# MIMXRT1052 register map
Vendor: nxp.com; File version: 1.0
CPU: CM7 r0p1, little endian, MPU, FPU, VTOR, 4 interrupt priority bits
Registers are 32-bit, read-write, reset 0x0 unless marked. A register's access mark holds for its fields unless they carry their own. Offsets are from the block's base; [hi:lo] are bit positions; {n}, {i} and the like mark numbered series; 'fields as' and 'values as' point back to an identical list.

## IOMUXC_GPR
Base 0x400AC000; register names take the prefix IOMUXC_GPR_
0x00 GPR0 ro — GPR0 General Purpose Register
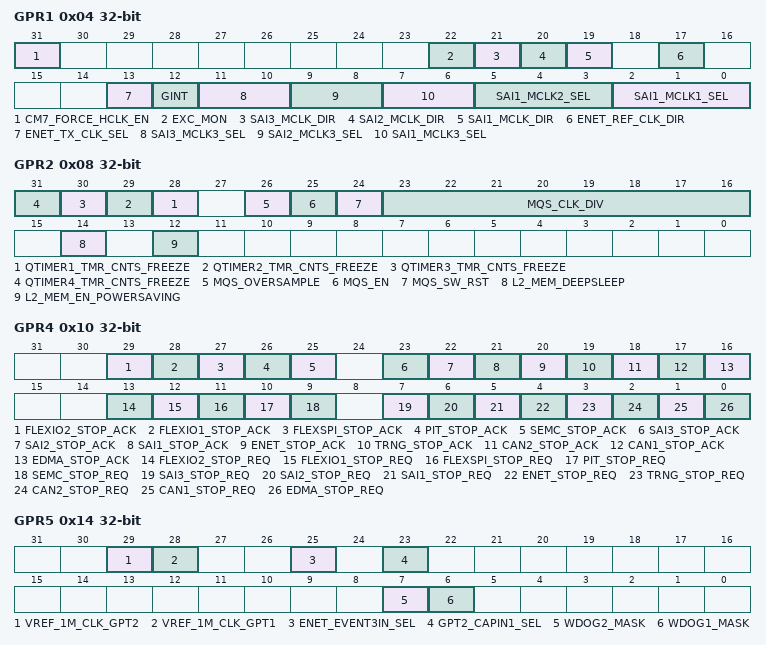
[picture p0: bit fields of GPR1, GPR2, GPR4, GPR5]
0x04 GPR1 — GPR1 General Purpose Register
  [31] CM7_FORCE_HCLK_EN — Arm CM7 platform AHB clock enable
    0=AHB clock is not running (gated) when CM7 is sleeping and TCM is not accessible; 1=AHB clock is running (enabled) when CM7 is sleeping and TCM is accessible
  [22] EXC_MON — Exclusive monitor response select of illegal command
    0=OKAY response; 1=SLVError response
  [21] SAI3_MCLK_DIR — SAI3_MCLK signal direction control. Sets the direction for the SAI3_MCLK pin function.
    0=SAI3_MCLK is input signal; 1=SAI3_MCLK is output signal
  [20] SAI2_MCLK_DIR — SAI2_MCLK signal direction control. Sets the direction for the SAI2_MCLK pin function.
    0=SAI2_MCLK is input signal; 1=SAI2_MCLK is output signal
  [19] SAI1_MCLK_DIR — SAI1_MCLK signal direction control. Sets the direction for the SAI1_MCLK pin function.
    0=SAI1_MCLK is input signal; 1=SAI1_MCLK is output signal
  [17] ENET_REF_CLK_DIR — ENET_REF_CLK direction control
    0=ENET_REF_CLK is input; 1=ENET_REF_CLK is output driven by ref_enetpll0
  [13] ENET_TX_CLK_SEL — ENET_TX_CLK select
    0=Do not use; 1=ENET_TX_CLK is the 25MHz MII clock
  [12] GINT — Global Interrupt
    0=Global interrupt request is not asserted; 1=Global interrupt request is asserted. Interrupt is issued to Arm M7 IRQ#41 and GPC
  [11:10] SAI3_MCLK3_SEL — SAI3 MCLK3 source select
    0=ccm.spdif0_clk_root; 1=iomux.spdif_tx_clk2; 2=spdif.spdif_srclk; 3=spdif.spdif_outclock
  [9:8] SAI2_MCLK3_SEL — SAI2 MCLK3 source select
    values as SAI3_MCLK3_SEL
  [7:6] SAI1_MCLK3_SEL — SAI1 MCLK3 source select
    values as SAI3_MCLK3_SEL
  [5:3] SAI1_MCLK2_SEL — SAI1 MCLK2 source select
    0=SAI1_CLK_ROOT; 1=SAI2_CLK_ROOT; 2=SAI3_CLK_ROOT; 3=iomux.sai1_ipg_clk_sai_mclk; 4=iomux.sai2_ipg_clk_sai_mclk; 5=iomux.sai3_ipg_clk_sai_mclk
  [2:0] SAI1_MCLK1_SEL — SAI1 MCLK1 source select
    values as SAI1_MCLK2_SEL
0x08 GPR2 — GPR2 General Purpose Register
  [n+27] QTIMER{n}_TMR_CNTS_FREEZE (n=1..4) — QTIMER{n} timer counter freeze
    0=Timer counter works normally; 1=Reset counter and ouput flags
  [26] MQS_OVERSAMPLE — Medium Quality Sound (MQS) Oversample
    0=32; 1=64
  [25] MQS_EN — MQS enable.
    0=Disable MQS; 1=Enable MQS
  [24] MQS_SW_RST — MQS software reset
    0=Exit software reset for MQS; 1=Enable software reset for MQS
  [23:16] MQS_CLK_DIV — Divider ratio control for mclk from hmclk. mclk frequency = 1/(n+1) * hmclk frequency.
    {v}=DIVIDE_{v+1} (mclk frequency = 1/{v+1} * hmclk frequency) (v=0..255)
  [14] L2_MEM_DEEPSLEEP — This bit controls how memory (OCRAM) enters Deep Sleep mode (shutdown periphery power, but maintain memory contents, outputs of memory are pulled low)
    0=No force sleep control supported, memory deep sleep mode only entered when whole system in stop mode (OCRAM in normal mode); 1=Force memory into deep sleep mode (OCRAM in power saving mode)
  [12] L2_MEM_EN_POWERSAVING — Enable power saving features on memory
    0=Enters power saving mode only when chip is in SUSPEND mode; 1=Controlled by L2_MEM_DEEPSLEEP bitfield
0x0C GPR3 reset 0xFFF0 — GPR3 General Purpose Register
  [4] DCP_KEY_SEL — Select 128-bit DCP key from 256-bit key from SNVS Master Key
    0=Select [127:0] from SNVS Master Key as DCP key; 1=Select [255:128] from SNVS Master Key as DCP key
0x10 GPR4 — GPR4 General Purpose Register
  [29] FLEXIO2_STOP_ACK ro — FLEXIO2 stop acknowledge
    0=FLEXIO2 stop acknowledge is not asserted; 1=FLEXIO2 stop acknowledge is asserted (FLEXIO2 is in STOP mode)
  [28] FLEXIO1_STOP_ACK ro — FLEXIO1 stop acknowledge
    0=FLEXIO1 stop acknowledge is not asserted; 1=FLEXIO1 stop acknowledge is asserted
  [27] FLEXSPI_STOP_ACK ro — FLEXSPI stop acknowledge
    0=FLEXSPI stop acknowledge is not asserted; 1=FLEXSPI stop acknowledge is asserted
  [26] PIT_STOP_ACK ro — PIT stop acknowledge
    0=PIT stop acknowledge is not asserted; 1=PIT stop acknowledge is asserted
  [25] SEMC_STOP_ACK ro — SEMC stop acknowledge
    0=SEMC stop acknowledge is not asserted; 1=SEMC stop acknowledge is asserted
  [23] SAI3_STOP_ACK ro — SAI3 stop acknowledge
    0=SAI3 stop acknowledge is not asserted; 1=SAI3 stop acknowledge is asserted
  [22] SAI2_STOP_ACK ro — SAI2 stop acknowledge
    0=SAI2 stop acknowledge is not asserted; 1=SAI2 stop acknowledge is asserted
  [21] SAI1_STOP_ACK ro — SAI1 stop acknowledge
    0=SAI1 stop acknowledge is not asserted; 1=SAI1 stop acknowledge is asserted
  [20] ENET_STOP_ACK ro — ENET stop acknowledge
    0=ENET stop acknowledge is not asserted; 1=ENET stop acknowledge is asserted
  [19] TRNG_STOP_ACK ro — TRNG stop acknowledge
    0=TRNG stop acknowledge is not asserted; 1=TRNG stop acknowledge is asserted
  [18] CAN2_STOP_ACK ro — CAN2 stop acknowledge
    0=CAN2 stop acknowledge is not asserted; 1=CAN2 stop acknowledge is asserted
  [17] CAN1_STOP_ACK ro — CAN1 stop acknowledge
    0=CAN1 stop acknowledge is not asserted; 1=CAN1 stop acknowledge is asserted
  [16] EDMA_STOP_ACK ro — EDMA stop acknowledge
    0=EDMA stop acknowledge is not asserted; 1=EDMA stop acknowledge is asserted (EDMA is in STOP mode)
  [13] FLEXIO2_STOP_REQ — FlexIO2 stop request
    0=stop request off; 1=stop request on
  [12] FLEXIO1_STOP_REQ — FlexIO1 stop request
    0=stop request off; 1=stop request on
  [11] FLEXSPI_STOP_REQ — FlexSPI stop request
    0=stop request off; 1=stop request on
  [10] PIT_STOP_REQ — PIT stop request
    0=stop request off; 1=stop request on
  [9] SEMC_STOP_REQ — SEMC stop request
    0=stop request off; 1=stop request on
  [7] SAI3_STOP_REQ — SAI3 stop request
    0=stop request off; 1=stop request on
  [6] SAI2_STOP_REQ — SAI2 stop request
    0=stop request off; 1=stop request on
  [5] SAI1_STOP_REQ — SAI1 stop request
    0=stop request off; 1=stop request on
  [4] ENET_STOP_REQ — ENET stop request
    0=stop request off; 1=stop request on
  [3] TRNG_STOP_REQ — TRNG stop request
    0=stop request off; 1=stop request on
  [2] CAN2_STOP_REQ — CAN2 stop request
    0=stop request off; 1=stop request on
  [1] CAN1_STOP_REQ — CAN1 stop request
    0=stop request off; 1=stop request on
  [0] EDMA_STOP_REQ — EDMA stop request
    0=stop request off; 1=stop request on
0x14 GPR5 — GPR5 General Purpose Register
  [29] VREF_1M_CLK_GPT2 — GPT2 1 MHz clock source select
    0=GPT2 ipg_clk_highfreq driven by IPG_PERCLK. IPG_PERCLK is derived from either BUS clock or OSC_24M clock. See CCM chapter for more information; 1=GPT2 ipg_clk_highfreq driven by anatop 1 MHz clock. Anatop 1M clock is derived from the OSC_RC_24M clock. It has two versions: corrected by 32k clock or un-corrected. See the XTALOSC24M_OSC_CONFIG2 register for more details
  [28] VREF_1M_CLK_GPT1 — GPT1 1 MHz clock source select
    0=GPT1 ipg_clk_highfreq driven by IPG_PERCLK. IPG_PERCLK is derived from either BUS clock or OSC_24M clock. See CCM chapter for more information; 1=GPT1 ipg_clk_highfreq driven by anatop 1 MHz clock. Anatop 1M clock is derived from the OSC_RC_24M clock. It has two versions: corrected by 32k clock or un-corrected. See the XTALOSC24M_OSC_CONFIG2 register for more details
  [25] ENET_EVENT3IN_SEL — ENET input timer event3 source select
    0=event3 source input from pad; 1=event3 source input from gpt2.ipp_do_cmpout1
  [23] GPT2_CAPIN1_SEL — GPT2 input capture channel 1 source select
    0=source from pad; 1=source from enet1.ipp_do_mac0_timer[3]
  [7] WDOG2_MASK — WDOG2 Timeout Mask
    0=WDOG2 Timeout behaves normally; 1=WDOG2 Timeout is masked
  [6] WDOG1_MASK — WDOG1 Timeout Mask
    0=WDOG1 Timeout behaves normally; 1=WDOG1 Timeout is masked
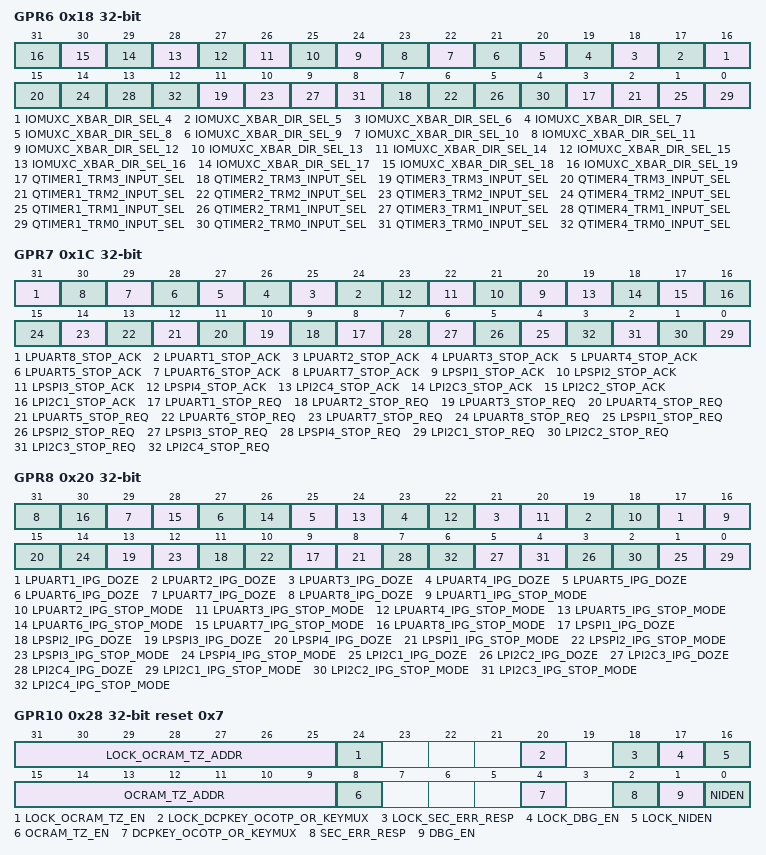
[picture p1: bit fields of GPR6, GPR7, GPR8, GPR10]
0x18 GPR6 — GPR6 General Purpose Register
  [n+12] IOMUXC_XBAR_DIR_SEL_{n} (n=4..19) — IOMUXC XBAR1_INOUT{n} function direction select
    0=XBAR1_INOUT as input; 1=XBAR1_INOUT as output
  [4n-1] QTIMER{n}_TRM3_INPUT_SEL (n=1..4) — QTIMER{n} TMR3 input select
    0=input from IOMUX; 1=input from XBAR
  [4n-2] QTIMER{n}_TRM2_INPUT_SEL (n=1..4) — QTIMER{n} TMR2 input select
    0=input from IOMUX; 1=input from XBAR
  [4n-3] QTIMER{n}_TRM1_INPUT_SEL (n=1..4) — QTIMER{n} TMR1 input select
    0=input from IOMUX; 1=input from XBAR
  [4n-4] QTIMER{n}_TRM0_INPUT_SEL (n=1..4) — QTIMER{n} TMR0 input select
    0=input from IOMUX; 1=input from XBAR
0x1C GPR7 — GPR7 General Purpose Register
  [31] LPUART8_STOP_ACK ro — LPUART8 stop acknowledge
    0=stop acknowledge is not asserted; 1=stop acknowledge is asserted (the module is in Stop mode)
  [n+23] LPUART{n}_STOP_ACK ro (n=1..7) — LPUART{n} stop acknowledge
    0=stop acknowledge is not asserted; 1=stop acknowledge is asserted
  [n+19] LPSPI{n}_STOP_ACK ro (n=1..4) — LPSPI{n} stop acknowledge
    values as LPUART1_STOP_ACK
  [19] LPI2C4_STOP_ACK ro — LPI2C4 stop acknowledge
    values as LPUART1_STOP_ACK
  [18] LPI2C3_STOP_ACK ro — LPI2C3 stop acknowledge
    values as LPUART1_STOP_ACK
  [17] LPI2C2_STOP_ACK ro — LPI2C2 stop acknowledge
    values as LPUART1_STOP_ACK
  [16] LPI2C1_STOP_ACK ro — LPI2C1 stop acknowledge
    values as LPUART8_STOP_ACK
  [n+7] LPUART{n}_STOP_REQ (n=1..8) — LPUART{n} stop request
    0=stop request off; 1=stop request on
  [n+3] LPSPI{n}_STOP_REQ (n=1..4) — LPSPI{n} stop request
    0=stop request off; 1=stop request on
  [n-1] LPI2C{n}_STOP_REQ (n=1..4) — LPI2C{n} stop request
    0=stop request off; 1=stop request on
0x20 GPR8 — GPR8 General Purpose Register
  [2n+15] LPUART{n}_IPG_DOZE (n=1..8) — LPUART{n} ipg_doze mode
    0=not in doze mode; 1=in doze mode
  [2n+14] LPUART{n}_IPG_STOP_MODE (n=1..8) — LPUART{n} stop mode selection, cannot change when ipg_stop is asserted.
    0=the module is functional in Stop mode; 1=the module is NOT functional in Stop mode, when this bit is equal to 1 and ipg_stop is asserted
  [2n+7] LPSPI{n}_IPG_DOZE (n=1..4) — LPSPI{n} ipg_doze mode
    0=not in doze mode; 1=in doze mode
  [2n+6] LPSPI{n}_IPG_STOP_MODE (n=1..4) — LPSPI{n} stop mode selection, cannot change when ipg_stop is asserted.
    values as LPUART1_IPG_STOP_MODE
  [2n-1] LPI2C{n}_IPG_DOZE (n=1..4) — LPI2C{n} ipg_doze mode
    0=not in doze mode; 1=in doze mode
  [2n-2] LPI2C{n}_IPG_STOP_MODE (n=1..4) — LPI2C{n} stop mode selection, cannot change when ipg_stop is asserted.
    values as LPUART1_IPG_STOP_MODE
0x24 GPR9 ro — GPR9 General Purpose Register
0x28 GPR10 reset 0x7 — GPR10 General Purpose Register
  [31:25] LOCK_OCRAM_TZ_ADDR — Lock OCRAM_TZ_ADDR field for changes
    0=Field is not locked; 1=Field is locked (read access only)
  [24] LOCK_OCRAM_TZ_EN — Lock OCRAM_TZ_EN field for changes
    0=Field is not locked; 1=Field is locked (read access only)
  [20] LOCK_DCPKEY_OCOTP_OR_KEYMUX — Lock DCP Key OCOTP/Key MUX selection bit
    0=Field is not locked; 1=Field is locked (read access only)
  [18] LOCK_SEC_ERR_RESP — Lock SEC_ERR_RESP field for changes
    0=Field is not locked; 1=Field is locked (read access only)
  [17] LOCK_DBG_EN — Lock DBG_EN field for changes
    0=Field is not locked; 1=Field is locked (read access only)
  [16] LOCK_NIDEN — Lock NIDEN field for changes
    0=Field is not locked; 1=Field is locked (read access only)
  [15:9] OCRAM_TZ_ADDR — OCRAM TrustZone (TZ) start address
  [8] OCRAM_TZ_EN — OCRAM TrustZone (TZ) enable.
    0=The TrustZone feature is disabled. Entire OCRAM space is available for all access types (secure/non-secure/user/supervisor); 1=The TrustZone feature is enabled. Access to address in the range specified by [ENDADDR:STARTADDR] follows the execution mode access policy described in CSU chapter
  [4] DCPKEY_OCOTP_OR_KEYMUX — DCP Key selection bit.
    0=Select key from SNVS Master Key; 1=Select key from OCOTP (SW_GP2)
  [2] SEC_ERR_RESP — Security error response enable
    0=OKEY response; 1=SLVError (default)
  [1] DBG_EN — Arm invasive debug enable
    0=Debug turned off; 1=Debug enabled (default)
  [0] NIDEN — Arm non-secure (non-invasive) debug enable
    0=Debug turned off; 1=Debug enabled (default)
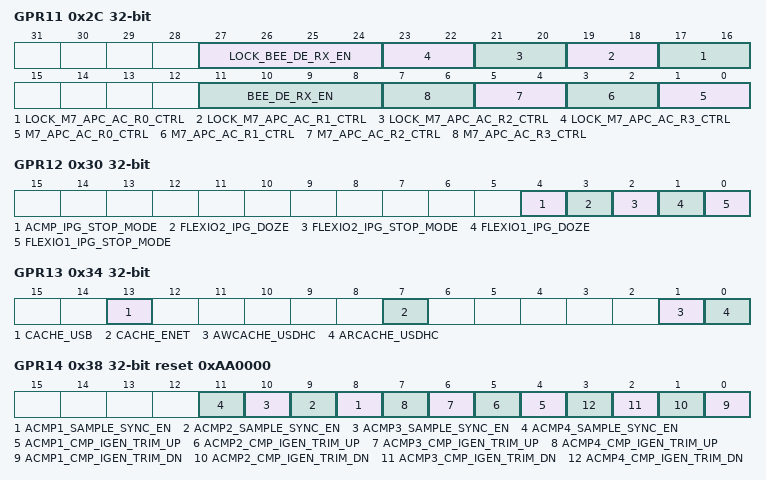
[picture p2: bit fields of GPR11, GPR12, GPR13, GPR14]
0x2C GPR11 — GPR11 General Purpose Register
  [27:24] LOCK_BEE_DE_RX_EN — Lock BEE_DE_RX_EN[n] (n = 3 to 0) field for changes
    0=Field is not locked; 1=Field is locked (read access only)
  [2n+17:2n+16] LOCK_M7_APC_AC_R{n}_CTRL (n=0..3) — Lock M7_APC_AC_R{n}_CTRL field for changes
    0=Field is not locked; 1=Field is locked (read access only)
  [11:8] BEE_DE_RX_EN — BEE data decryption of memory region-n (n = 3 to 0).
    0=FlexSPI data decryption disabled; 1=FlexSPI data decryption enabled
  [2n+1:2n] M7_APC_AC_R{n}_CTRL (n=0..3) — Access control of memory region-{n}
    0=No access protection - All accesses are allowed; 1=M7 debug protection enabled - The APC block will block CM7 breakpoints, watchpoints and trace to the GPR_M7_APC_AC_R{n}_TOP/BOT specified region (IOMUXC_GPR_GPR{2n+18} - IOMUXC_GPR_GPR{2n+19})
0x30 GPR12 — GPR12 General Purpose Register
  [4] ACMP_IPG_STOP_MODE — ACMP stop mode selection. Cannot change when ipg_stop is asserted.
    0=ACMP is functional in Stop mode; 1=When this bit is equal to 1'b1 and ipg_stop is asserted, ACMP is not functional in Stop mode
  [3] FLEXIO2_IPG_DOZE — FLEXIO2 ipg_doze mode
    0=FLEXIO2 is not in doze mode; 1=FLEXIO2 is in doze mode
  [2] FLEXIO2_IPG_STOP_MODE — FlexIO2 stop mode selection. Cannot change when ipg_stop is asserted.
    0=FlexIO2 is functional in Stop mode; 1=When this bit is equal to 1'b1 and ipg_stop is asserted, FlexIO2 is not functional in Stop mode
  [1] FLEXIO1_IPG_DOZE — FLEXIO1 ipg_doze mode
    0=FLEXIO1 is not in doze mode; 1=FLEXIO1 is in doze mode
  [0] FLEXIO1_IPG_STOP_MODE — FlexIO1 stop mode selection. Cannot change when ipg_stop is asserted.
    0=FlexIO1 is functional in Stop mode; 1=When this bit is equal to 1'b1 and ipg_stop is asserted, FlexIO1 is not functional in Stop mode
0x34 GPR13 — GPR13 General Purpose Register
  [13] CACHE_USB — USB block cacheable attribute value of AXI transactions
    0=Cacheable attribute is off for read/write transactions; 1=Cacheable attribute is on for read/write transactions
  [7] CACHE_ENET — ENET block cacheable attribute value of AXI transactions
    values as CACHE_USB
  [1] AWCACHE_USDHC — uSDHC block cacheable attribute value of AXI write transactions
    0=Cacheable attribute is off for write transactions; 1=Cacheable attribute is on for write transactions
  [0] ARCACHE_USDHC — uSDHC block cacheable attribute value of AXI read transactions
    0=Cacheable attribute is off for read transactions; 1=Cacheable attribute is on for read transactions
0x38 GPR14 reset 0xAA0000 — GPR14 General Purpose Register
  [n+7] ACMP{n}_SAMPLE_SYNC_EN (n=1..4) — ACMP{n} sample_lv source select
    0=select XBAR output; 1=select synced sample_lv
  [n+3] ACMP{n}_CMP_IGEN_TRIM_UP (n=1..4) — increases ACMP{n} internal bias current by 30%
    0=no increase; 1=increases
  [n-1] ACMP{n}_CMP_IGEN_TRIM_DN (n=1..4) — reduces ACMP{n} internal bias current by 30%
    0=no reduce; 1=reduces
0x3C GPR15 ro reset 0xFFFFFFFF — GPR15 General Purpose Register
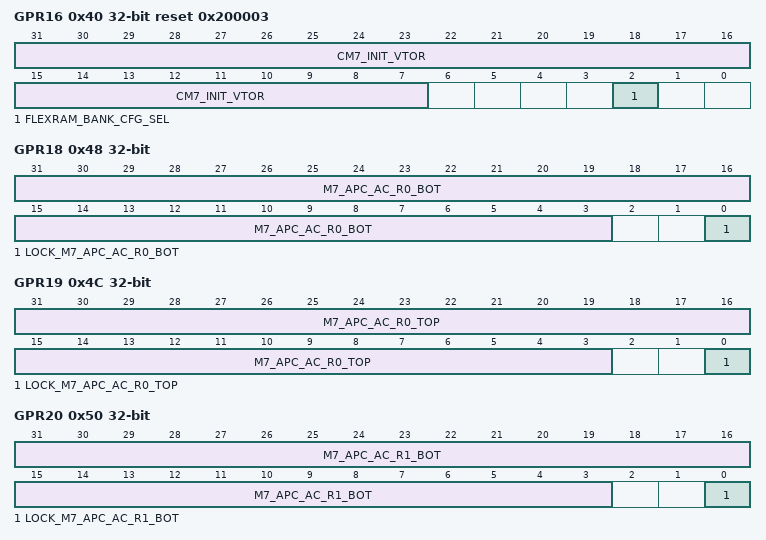
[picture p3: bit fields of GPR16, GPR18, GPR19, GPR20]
0x40 GPR16 reset 0x200003 — GPR16 General Purpose Register
  [31:7] CM7_INIT_VTOR — Vector table offset register out of reset
  [2] FLEXRAM_BANK_CFG_SEL — FlexRAM bank config source select
    0=use fuse value to config; 1=use FLEXRAM_BANK_CFG to config
0x44 GPR17 — GPR17 General Purpose Register
  [31:0] FLEXRAM_BANK_CFG — FlexRAM bank config value
0x48 GPR18 — GPR18 General Purpose Register
  [31:3] M7_APC_AC_R0_BOT — Access Permission Controller (APC) end address of memory region-0
  [0] LOCK_M7_APC_AC_R0_BOT — lock M7_APC_AC_R0_BOT field for changes
    0=M7_APC_AC_R0_BOT is not locked; 1=M7_APC_AC_R0_BOT is locked (read access only)
0x4C GPR19 — GPR19 General Purpose Register
  [31:3] M7_APC_AC_R0_TOP — Access Permission Controller (APC) start address of memory region-0
  [0] LOCK_M7_APC_AC_R0_TOP — lock M7_APC_AC_R0_TOP field for changes
    0=M7_APC_AC_R0_TOP is not locked; 1=M7_APC_AC_R0_TOP is locked (read access only)
0x50 GPR20 — GPR20 General Purpose Register
  [31:3] M7_APC_AC_R1_BOT — Access Permission Controller (APC) end address of memory region-1
  [0] LOCK_M7_APC_AC_R1_BOT — lock M7_APC_AC_R1_BOT field for changes
    0=M7_APC_AC_R1_BOT is not locked; 1=M7_APC_AC_R1_BOT is locked (read access only)
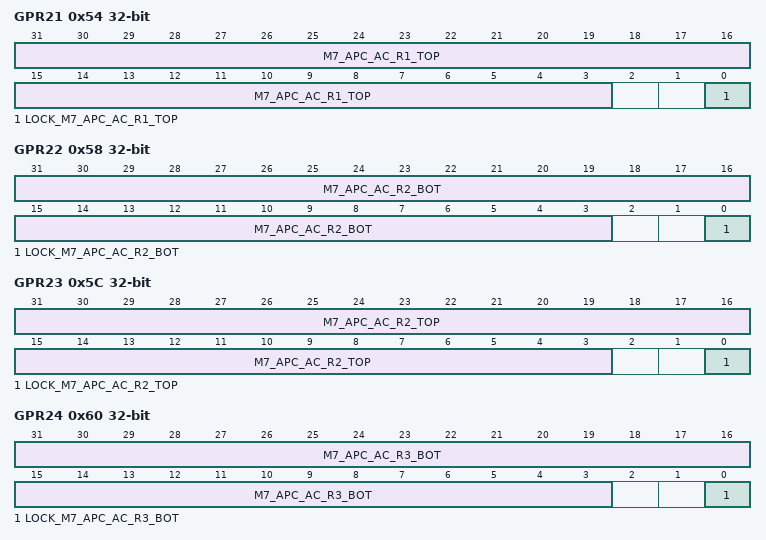
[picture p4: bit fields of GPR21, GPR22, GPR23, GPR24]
0x54 GPR21 — GPR21 General Purpose Register
  [31:3] M7_APC_AC_R1_TOP — Access Permission Controller (APC) start address of memory region-1
  [0] LOCK_M7_APC_AC_R1_TOP — lock M7_APC_AC_R1_TOP field for changes
    0=M7_APC_AC_R1_TOP is not locked; 1=M7_APC_AC_R1_TOP is locked (read access only)
0x58 GPR22 — GPR22 General Purpose Register
  [31:3] M7_APC_AC_R2_BOT — Access Permission Controller (APC) end address of memory region-2
  [0] LOCK_M7_APC_AC_R2_BOT — lock M7_APC_AC_R2_BOT field for changes
    0=M7_APC_AC_R2_BOT is not locked; 1=M7_APC_AC_R2_BOT is locked (read access only)
0x5C GPR23 — GPR23 General Purpose Register
  [31:3] M7_APC_AC_R2_TOP — Access Permission Controller (APC) start address of memory region-2
  [0] LOCK_M7_APC_AC_R2_TOP — lock M7_APC_AC_R2_TOP field for changes
    0=M7_APC_AC_R2_TOP is not locked; 1=M7_APC_AC_R2_TOP is locked (read access only)
0x60 GPR24 — GPR24 General Purpose Register
  [31:3] M7_APC_AC_R3_BOT — Access Permission Controller (APC) end address of memory region-3
  [0] LOCK_M7_APC_AC_R3_BOT — lock M7_APC_AC_R3_BOT field for changes
    0=M7_APC_AC_R3_BOT is not locked; 1=M7_APC_AC_R3_BOT is locked (read access only)
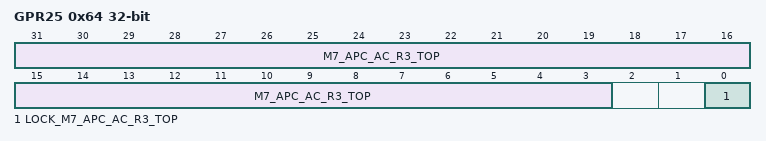
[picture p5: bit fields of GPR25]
0x64 GPR25 — GPR25 General Purpose Register
  [31:3] M7_APC_AC_R3_TOP — Access Permission Controller (APC) start address of memory region-3
  [0] LOCK_M7_APC_AC_R3_TOP — lock M7_APC_AC_R3_TOP field for changes
    0=M7_APC_AC_R3_TOP is not locked; 1=M7_APC_AC_R3_TOP is locked (read access only)
